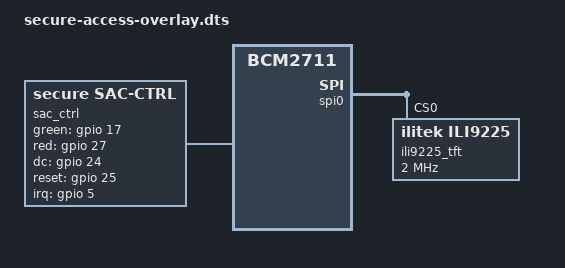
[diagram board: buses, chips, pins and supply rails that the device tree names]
/dts-v1/;
/plugin/;

/*
 * Device Tree overlay (Raspberry Pi 4 - bcm2711)
 *
 * Purpose:
 *   - Disable the default spidev user-space helper on SPI0 CS0 so this project
 *     can own the bus for the ILI9225 panel.
 *   - Instantiate ili9225@0 under &spi0 with conservative SPI clock.
 *   - Add platform node secure-access-ctrl with compatible "secure,sac-ctrl"
 *     consumed by sac_core_main.c probe(): GPIOs for LEDs and TFT control lines,
 *     tft-spi phandle to the SPI child, optional GPIO IRQ line for auth completion.
 *
 * Build:
 *   dtc -@ -I dts -O dtb -o dt/out/secure-access-overlay.dtbo dt/secure-access-overlay.dts
 *
 * Boot config (/boot/firmware/config.txt on Bookworm):
 *   dtparam=spi=on
 *   dtoverlay=secure-access-overlay
 */

/ {
	compatible = "brcm,bcm2711";

	/* Disable default spidev on CS0 so our TFT can own spi0.0 */
	fragment@0 {
		target = <&spidev0>;
		__overlay__ {
			status = "disabled";
		};
	};

	fragment@1 {
		target = <&spi0>;
		__overlay__ {
			status = "okay";
			#address-cells = <1>;
			#size-cells = <0>;

			ili9225_tft: ili9225@0 {
				compatible = "ilitek,ili9225";
				reg = <0>;
				spi-max-frequency = <2000000>;
				status = "okay";
			};
		};
	};

	fragment@2 {
		target-path = "/";
		__overlay__ {
			sac_ctrl: secure-access-ctrl {
				compatible = "secure,sac-ctrl";
				status = "okay";

				tft-spi = <&ili9225_tft>;

				green-gpios = <&gpio 17 0>;
				red-gpios = <&gpio 27 0>;
				dc-gpios = <&gpio 24 0>;
				reset-gpios = <&gpio 25 0>;

				interrupt-parent = <&gpio>;
				interrupts = <5 2>;
			};
		};
	};
};
